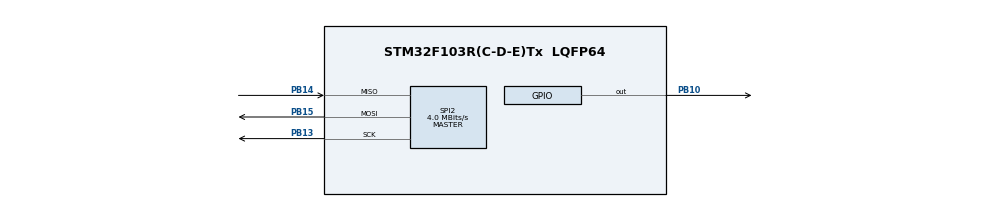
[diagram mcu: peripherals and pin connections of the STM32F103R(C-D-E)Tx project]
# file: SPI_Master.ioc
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Mcu.Family=STM32F1
Mcu.Name=STM32F103R(C-D-E)Tx
Mcu.Package=LQFP64
NVIC.PriorityGroup=NVIC_PRIORITYGROUP_4
PB10.Signal=GPIO_Output
PB13.Mode=Full_Duplex_Master
PB13.Signal=SPI2_SCK
PB14.Mode=Full_Duplex_Master
PB14.Signal=SPI2_MISO
PB15.Mode=Full_Duplex_Master
PB15.Signal=SPI2_MOSI
PD0-OSC_IN.Mode=HSE-External-Oscillator
PD0-OSC_IN.Signal=RCC_OSC_IN
PD1-OSC_OUT.Mode=HSE-External-Oscillator
PD1-OSC_OUT.Signal=RCC_OSC_OUT
ProjectManager.TargetToolchain=EWARM
RCC.APB1Freq_Value=8000000
RCC.APB2Freq_Value=8000000
RCC.SYSCLKSource=RCC_SYSCLKSOURCE_HSE
SPI2.CalculateBaudRate=4.0 MBits/s
SPI2.Mode=SPI_MODE_MASTER
board=SPI_Master

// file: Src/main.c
/**
  ******************************************************************************
  * File Name          : main.c
  * Description        : Main program body
  ******************************************************************************
  *
  * COPYRIGHT(c) 2016 STMicroelectronics
  *
  * Redistribution and use in source and binary forms, with or without modification,
  * are permitted provided that the following conditions are met:
  *   1. Redistributions of source code must retain the above copyright notice,
  *      this list of conditions and the following disclaimer.
  *   2. Redistributions in binary form must reproduce the above copyright notice,
  *      this list of conditions and the following disclaimer in the documentation
  *      and/or other materials provided with the distribution.
  *   3. Neither the name of STMicroelectronics nor the names of its contributors
  *      may be used to endorse or promote products derived from this software
  *      without specific prior written permission.
  *
  * THIS SOFTWARE IS PROVIDED BY THE COPYRIGHT HOLDERS AND CONTRIBUTORS "AS IS"
  * AND ANY EXPRESS OR IMPLIED WARRANTIES, INCLUDING, BUT NOT LIMITED TO, THE
  * IMPLIED WARRANTIES OF MERCHANTABILITY AND FITNESS FOR A PARTICULAR PURPOSE ARE
  * DISCLAIMED. IN NO EVENT SHALL THE COPYRIGHT HOLDER OR CONTRIBUTORS BE LIABLE
  * FOR ANY DIRECT, INDIRECT, INCIDENTAL, SPECIAL, EXEMPLARY, OR CONSEQUENTIAL
  * DAMAGES (INCLUDING, BUT NOT LIMITED TO, PROCUREMENT OF SUBSTITUTE GOODS OR
  * SERVICES; LOSS OF USE, DATA, OR PROFITS; OR BUSINESS INTERRUPTION) HOWEVER
  * CAUSED AND ON ANY THEORY OF LIABILITY, WHETHER IN CONTRACT, STRICT LIABILITY,
  * OR TORT (INCLUDING NEGLIGENCE OR OTHERWISE) ARISING IN ANY WAY OUT OF THE USE
  * OF THIS SOFTWARE, EVEN IF ADVISED OF THE POSSIBILITY OF SUCH DAMAGE.
  *
  ******************************************************************************
  */
#include "stm32f1xx_hal.h"

SPI_HandleTypeDef hspi2;

/* USER CODE BEGIN PV */
/* Private variables ---------------------------------------------------------*/

unsigned char d1='A';
unsigned char d2='B';

/* USER CODE END PV */

void SystemClock_Config(void);
static void MX_GPIO_Init(void);
static void MX_SPI2_Init(void);

/* USER CODE BEGIN PFP */
/* Private function prototypes -----------------------------------------------*/

/* USER CODE END PFP */

int main(void)
{

  /* MCU Configuration----------------------------------------------------------*/

  /* Reset of all peripherals, Initializes the Flash interface and the Systick. */
  HAL_Init();

  /* Configure the system clock */
  SystemClock_Config();

  /* Initialize all configured peripherals */
  MX_GPIO_Init();
  MX_SPI2_Init();

  /* Infinite loop */
  /* USER CODE BEGIN WHILE */

  HAL_GPIO_WritePin(GPIOB, GPIO_PIN_10, GPIO_PIN_SET);

  while (1)
  {
    HAL_GPIO_WritePin(GPIOB, GPIO_PIN_10, GPIO_PIN_RESET);

    HAL_SPI_Transmit(&hspi2, &d1, 1, 10);

    HAL_GPIO_WritePin(GPIOB, GPIO_PIN_10, GPIO_PIN_SET);
    HAL_Delay(500);

    HAL_GPIO_WritePin(GPIOB, GPIO_PIN_10, GPIO_PIN_RESET);
    HAL_SPI_Transmit(&hspi2, &d2, 1, 10);
    HAL_GPIO_WritePin(GPIOB, GPIO_PIN_10, GPIO_PIN_SET);
    HAL_Delay(500);

  /* USER CODE END WHILE */

  }
}

/** System Clock Configuration
*/
void SystemClock_Config(void)
{

  RCC_OscInitTypeDef RCC_OscInitStruct;
  RCC_ClkInitTypeDef RCC_ClkInitStruct;

  RCC_OscInitStruct.OscillatorType = RCC_OSCILLATORTYPE_HSE;
  RCC_OscInitStruct.HSEState = RCC_HSE_ON;
  RCC_OscInitStruct.PLL.PLLState = RCC_PLL_NONE;
  HAL_RCC_OscConfig(&RCC_OscInitStruct);

  RCC_ClkInitStruct.ClockType = RCC_CLOCKTYPE_SYSCLK;
  RCC_ClkInitStruct.SYSCLKSource = RCC_SYSCLKSOURCE_HSE;
  RCC_ClkInitStruct.AHBCLKDivider = RCC_SYSCLK_DIV1;
  RCC_ClkInitStruct.APB1CLKDivider = RCC_HCLK_DIV1;
  RCC_ClkInitStruct.APB2CLKDivider = RCC_HCLK_DIV1;
  HAL_RCC_ClockConfig(&RCC_ClkInitStruct, FLASH_LATENCY_0);

  HAL_SYSTICK_Config(HAL_RCC_GetHCLKFreq()/1000);

  HAL_SYSTICK_CLKSourceConfig(SYSTICK_CLKSOURCE_HCLK);

  /* SysTick_IRQn interrupt configuration */
  HAL_NVIC_SetPriority(SysTick_IRQn, 0, 0);
}

/* SPI2 init function */
void MX_SPI2_Init(void)
{

  hspi2.Instance = SPI2;
  hspi2.Init.Mode = SPI_MODE_MASTER;
  hspi2.Init.Direction = SPI_DIRECTION_2LINES;
  hspi2.Init.DataSize = SPI_DATASIZE_8BIT;
  hspi2.Init.CLKPolarity = SPI_POLARITY_LOW;
  hspi2.Init.CLKPhase = SPI_PHASE_1EDGE;
  hspi2.Init.NSS = SPI_NSS_SOFT;
  hspi2.Init.BaudRatePrescaler = SPI_BAUDRATEPRESCALER_2;
  hspi2.Init.FirstBit = SPI_FIRSTBIT_MSB;
  hspi2.Init.TIMode = SPI_TIMODE_DISABLED;
  hspi2.Init.CRCCalculation = SPI_CRCCALCULATION_DISABLED;
  hspi2.Init.CRCPolynomial = 10;
  HAL_SPI_Init(&hspi2);

}

/** Configure pins as
        * Analog
        * Input
        * Output
        * EVENT_OUT
        * EXTI
*/
void MX_GPIO_Init(void)
{

  GPIO_InitTypeDef GPIO_InitStruct;

  /* GPIO Ports Clock Enable */
  __GPIOD_CLK_ENABLE();
  __GPIOB_CLK_ENABLE();

  /*Configure GPIO pin : PB10 */
  GPIO_InitStruct.Pin = GPIO_PIN_10;
  GPIO_InitStruct.Mode = GPIO_MODE_OUTPUT_PP;
  GPIO_InitStruct.Speed = GPIO_SPEED_LOW;
  HAL_GPIO_Init(GPIOB, &GPIO_InitStruct);

}

/************************ (C) COPYRIGHT STMicroelectronics *****END OF FILE****/
